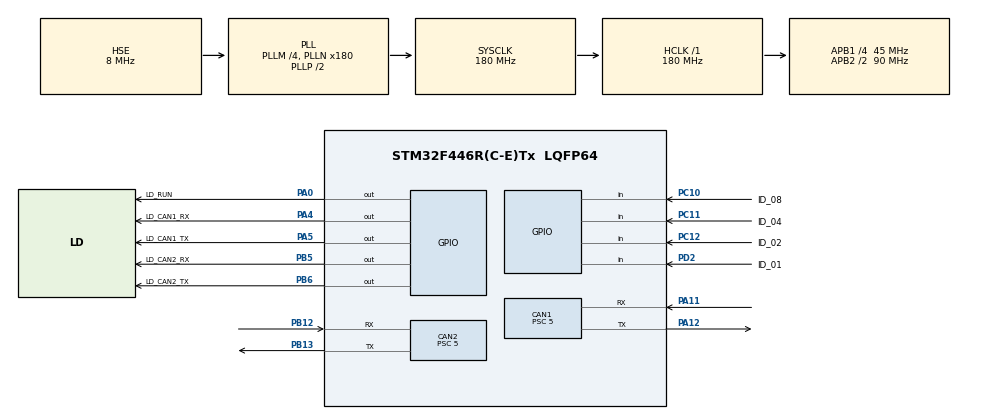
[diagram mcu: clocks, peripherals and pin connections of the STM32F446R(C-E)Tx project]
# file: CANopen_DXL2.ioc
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CAN1.ABOM=ENABLE
CAN1.BS1=CAN_BS1_5TQ
CAN1.BS2=CAN_BS2_3TQ
CAN1.CalculateBaudRate=1000000
CAN1.CalculateTimeBit=1000
CAN1.CalculateTimeQuantum=111.11111111111111
CAN1.Prescaler=5
CAN2.ABOM=ENABLE
CAN2.BS1=CAN_BS1_5TQ
CAN2.BS2=CAN_BS2_3TQ
CAN2.CalculateBaudRate=1000000
CAN2.CalculateTimeBit=1000
CAN2.CalculateTimeQuantum=111.11111111111111
CAN2.Prescaler=5
FREERTOS.Queues01=zerPosi,40,MotionPacket_TypeDef,0,Dynamic,NULL,NULL;zerCmd_rx,40,BypassPacket_TypeDef,0,Dynamic,NULL,NULL;zerCmd_tx,40,BypassPacket_TypeDef,0,Dynamic,NULL,NULL
FREERTOS.Tasks01=defaultTask,24,128,StartDefaultTask,Default,NULL,Dynamic,NULL,NULL;MRS_Task,46,1024,main_MRS,As external,NULL,Dynamic,NULL,NULL;zeroErrTask,48,1024,main_ZeroErr,As external,NULL,Dynamic,NULL,NULL
FREERTOS.configTOTAL_HEAP_SIZE=20480
FREERTOS.configUSE_NEWLIB_REENTRANT=1
Mcu.Family=STM32F4
Mcu.Name=STM32F446R(C-E)Tx
Mcu.Package=LQFP64
NVIC.CAN1_RX0_IRQn=true\:5\:0\:false\:false\:true\:true\:true\:true\:true
NVIC.CAN1_TX_IRQn=true\:5\:0\:false\:false\:true\:true\:true\:true\:true
NVIC.CAN2_RX0_IRQn=true\:5\:0\:false\:false\:true\:true\:true\:true\:true
NVIC.CAN2_TX_IRQn=true\:5\:0\:false\:false\:true\:true\:true\:true\:true
NVIC.PriorityGroup=NVIC_PRIORITYGROUP_4
NVIC.TIM4_IRQn=true\:15\:0\:false\:false\:true\:false\:false\:true\:true
NVIC.TIM8_TRG_COM_TIM14_IRQn=true\:5\:0\:false\:false\:true\:true\:true\:true\:true
NVIC.TimeBase=TIM4_IRQn
NVIC.TimeBaseIP=TIM4
PA0-WKUP.GPIO_Label=LD_RUN
PA0-WKUP.Signal=GPIO_Output
PA11.Mode=CAN_Activate
PA11.Signal=CAN1_RX
PA12.Mode=CAN_Activate
PA12.Signal=CAN1_TX
PA13.Mode=Trace_Asynchronous_SW
PA13.Signal=SYS_JTMS-SWDIO
PA14.Mode=Trace_Asynchronous_SW
PA14.Signal=SYS_JTCK-SWCLK
PA4.GPIO_Label=LD_CAN1_RX
PA4.Signal=GPIO_Output
PA5.GPIO_Label=LD_CAN1_TX
PA5.Signal=GPIO_Output
PB12.Mode=CAN_Activate
PB12.Signal=CAN2_RX
PB13.Mode=CAN_Activate
PB13.Signal=CAN2_TX
PB3.Mode=Trace_Asynchronous_SW
PB3.Signal=SYS_JTDO-SWO
PB5.GPIO_Label=LD_CAN2_RX
PB5.Signal=GPIO_Output
PB6.GPIO_Label=LD_CAN2_TX
PB6.Signal=GPIO_Output
PC10.GPIO_Label=ID_08
PC10.Signal=GPIO_Input
PC11.GPIO_Label=ID_04
PC11.Signal=GPIO_Input
PC12.GPIO_Label=ID_02
PC12.Signal=GPIO_Input
PD2.GPIO_Label=ID_01
PD2.Signal=GPIO_Input
PH0-OSC_IN.Mode=HSE-External-Oscillator
PH0-OSC_IN.Signal=RCC_OSC_IN
PH1-OSC_OUT.Mode=HSE-External-Oscillator
PH1-OSC_OUT.Signal=RCC_OSC_OUT
ProjectManager.HeapSize=0x200
ProjectManager.StackSize=0x400
ProjectManager.TargetToolchain=CMake
RCC.AHBFreq_Value=180000000
RCC.APB1CLKDivider=RCC_HCLK_DIV4
RCC.APB1Freq_Value=45000000
RCC.APB1TimFreq_Value=90000000
RCC.APB2CLKDivider=RCC_HCLK_DIV2
RCC.APB2Freq_Value=90000000
RCC.APB2TimFreq_Value=180000000
RCC.CortexFreq_Value=180000000
RCC.HCLKFreq_Value=180000000
RCC.HSE_VALUE=8000000
RCC.PLLM=4
RCC.PLLN=180
RCC.PLLSourceVirtual=RCC_PLLSOURCE_HSE
RCC.SYSCLKFreq_VALUE=180000000
RCC.SYSCLKSource=RCC_SYSCLKSOURCE_PLLCLK
RCC.USBFreq_Value=180000000
RCC.VCOOutputFreq_Value=360000000
TIM14.Prescaler=44
VP_FREERTOS_VS_CMSIS_V2.Mode=CMSIS_V2
VP_SYS_VS_tim4.Mode=TIM4
VP_TIM14_VS_ClockSourceINT.Mode=Enable_Timer
board=custom

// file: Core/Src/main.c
/* USER CODE BEGIN Header */
/**
  ******************************************************************************
  * @file           : main.c
  * @brief          : Main program body
  ******************************************************************************
  * @attention
  *
  * Copyright (c) 2023 STMicroelectronics.
  * All rights reserved.
  *
  * This software is licensed under terms that can be found in the LICENSE file
  * in the root directory of this software component.
  * If no LICENSE file comes with this software, it is provided AS-IS.
  *
  ******************************************************************************
  */
/* USER CODE END Header */
#include "main.h"
#include "cmsis_os.h"
#include "can.h"
#include "tim.h"
#include "gpio.h"

void SystemClock_Config(void);
void MX_FREERTOS_Init(void);

/* USER CODE BEGIN 0 */
#ifdef __cplusplus
extern "C" int _write(int32_t file, uint8_t *ptr, int32_t len) {
#else
int _write(int32_t file, uint8_t *ptr, int32_t len) {
#endif
    for(int32_t i = 0; i < len; ++i) { ITM_SendChar(*ptr++); }
    return len;
}
/* USER CODE END 0 */

int main(void)
{

  /* MCU Configuration--------------------------------------------------------*/

  /* Reset of all peripherals, Initializes the Flash interface and the Systick. */
  HAL_Init();

  /* Configure the system clock */
  SystemClock_Config();

  /* Initialize all configured peripherals */
  MX_GPIO_Init();
  MX_CAN1_Init();
  MX_CAN2_Init();
  MX_TIM14_Init();

  /* Init scheduler */
  osKernelInitialize();  /* Call init function for freertos objects (in freertos.c) */
  MX_FREERTOS_Init();

  /* Start scheduler */
  osKernelStart();

  /* We should never get here as control is now taken by the scheduler */
  /* Infinite loop */
  while (1)
  {

  }
}

void SystemClock_Config(void)
{
  RCC_OscInitTypeDef RCC_OscInitStruct = {0};
  RCC_ClkInitTypeDef RCC_ClkInitStruct = {0};

  /** Configure the main internal regulator output voltage
  */
  __HAL_RCC_PWR_CLK_ENABLE();
  __HAL_PWR_VOLTAGESCALING_CONFIG(PWR_REGULATOR_VOLTAGE_SCALE1);

  /** Initializes the RCC Oscillators according to the specified parameters
  * in the RCC_OscInitTypeDef structure.
  */
  RCC_OscInitStruct.OscillatorType = RCC_OSCILLATORTYPE_HSE;
  RCC_OscInitStruct.HSEState = RCC_HSE_ON;
  RCC_OscInitStruct.PLL.PLLState = RCC_PLL_ON;
  RCC_OscInitStruct.PLL.PLLSource = RCC_PLLSOURCE_HSE;
  RCC_OscInitStruct.PLL.PLLM = 4;
  RCC_OscInitStruct.PLL.PLLN = 180;
  RCC_OscInitStruct.PLL.PLLP = RCC_PLLP_DIV2;
  RCC_OscInitStruct.PLL.PLLQ = 2;
  RCC_OscInitStruct.PLL.PLLR = 2;
  if (HAL_RCC_OscConfig(&RCC_OscInitStruct) != HAL_OK)
  {
    Error_Handler();
  }

  /** Activate the Over-Drive mode
  */
  if (HAL_PWREx_EnableOverDrive() != HAL_OK)
  {
    Error_Handler();
  }

  /** Initializes the CPU, AHB and APB buses clocks
  */
  RCC_ClkInitStruct.ClockType = RCC_CLOCKTYPE_HCLK|RCC_CLOCKTYPE_SYSCLK
                              |RCC_CLOCKTYPE_PCLK1|RCC_CLOCKTYPE_PCLK2;
  RCC_ClkInitStruct.SYSCLKSource = RCC_SYSCLKSOURCE_PLLCLK;
  RCC_ClkInitStruct.AHBCLKDivider = RCC_SYSCLK_DIV1;
  RCC_ClkInitStruct.APB1CLKDivider = RCC_HCLK_DIV4;
  RCC_ClkInitStruct.APB2CLKDivider = RCC_HCLK_DIV2;

  if (HAL_RCC_ClockConfig(&RCC_ClkInitStruct, FLASH_LATENCY_5) != HAL_OK)
  {
    Error_Handler();
  }
}

void HAL_TIM_PeriodElapsedCallback(TIM_HandleTypeDef *htim)
{
  if (htim->Instance == TIM4) {
    HAL_IncTick();
  }
}

void Error_Handler(void)
{
  __disable_irq();
  while (1)
  {
  }
}

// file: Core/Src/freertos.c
/* USER CODE BEGIN Header */
/**
  ******************************************************************************
  * File Name          : freertos.c
  * Description        : Code for freertos applications
  ******************************************************************************
  * @attention
  *
  * Copyright (c) 2023 STMicroelectronics.
  * All rights reserved.
  *
  * This software is licensed under terms that can be found in the LICENSE file
  * in the root directory of this software component.
  * If no LICENSE file comes with this software, it is provided AS-IS.
  *
  ******************************************************************************
  */
/* USER CODE END Header */

#include "FreeRTOS.h"
#include "task.h"
#include "main.h"
#include "cmsis_os.h"

/* USER CODE BEGIN Includes */
#include "main_MRS.h"
#include "main_ZeroErr.h"
/* USER CODE END Includes */

/* Definitions for defaultTask */
osThreadId_t defaultTaskHandle;
const osThreadAttr_t defaultTask_attributes = {
  .name = "defaultTask",
  .stack_size = 128 * 4,
  .priority = (osPriority_t) osPriorityNormal,
};
/* Definitions for MRS_Task */
osThreadId_t MRS_TaskHandle;
const osThreadAttr_t MRS_Task_attributes = {
  .name = "MRS_Task",
  .stack_size = 1024 * 4,
  .priority = (osPriority_t) osPriorityHigh6,
};
/* Definitions for zeroErrTask */
osThreadId_t zeroErrTaskHandle;
const osThreadAttr_t zeroErrTask_attributes = {
  .name = "zeroErrTask",
  .stack_size = 1024 * 4,
  .priority = (osPriority_t) osPriorityRealtime,
};
/* Definitions for zerPosi */
osMessageQueueId_t zerPosiHandle;
const osMessageQueueAttr_t zerPosi_attributes = {
  .name = "zerPosi"
};
/* Definitions for zerCmd_rx */
osMessageQueueId_t zerCmd_rxHandle;
const osMessageQueueAttr_t zerCmd_rx_attributes = {
  .name = "zerCmd_rx"
};
/* Definitions for zerCmd_tx */
osMessageQueueId_t zerCmd_txHandle;
const osMessageQueueAttr_t zerCmd_tx_attributes = {
  .name = "zerCmd_tx"
};

void StartDefaultTask(void *argument);
extern void main_MRS(void *argument);
extern void main_ZeroErr(void *argument);

void MX_FREERTOS_Init(void); /* (MISRA C 2004 rule 8.1) */

void MX_FREERTOS_Init(void) {

  /* Create the queue(s) */
  /* creation of zerPosi */
  zerPosiHandle = osMessageQueueNew (40, sizeof(MotionPacket_TypeDef), &zerPosi_attributes);

  /* creation of zerCmd_rx */
  zerCmd_rxHandle = osMessageQueueNew (40, sizeof(BypassPacket_TypeDef), &zerCmd_rx_attributes);

  /* creation of zerCmd_tx */
  zerCmd_txHandle = osMessageQueueNew (40, sizeof(BypassPacket_TypeDef), &zerCmd_tx_attributes);

  /* Create the thread(s) */
  /* creation of defaultTask */
  defaultTaskHandle = osThreadNew(StartDefaultTask, NULL, &defaultTask_attributes);

  /* creation of MRS_Task */
  MRS_TaskHandle = osThreadNew(main_MRS, NULL, &MRS_Task_attributes);

  /* creation of zeroErrTask */
  zeroErrTaskHandle = osThreadNew(main_ZeroErr, NULL, &zeroErrTask_attributes);

}

void StartDefaultTask(void *argument)
{
  for(;;)
  {
    osDelay(1);
  }
}
